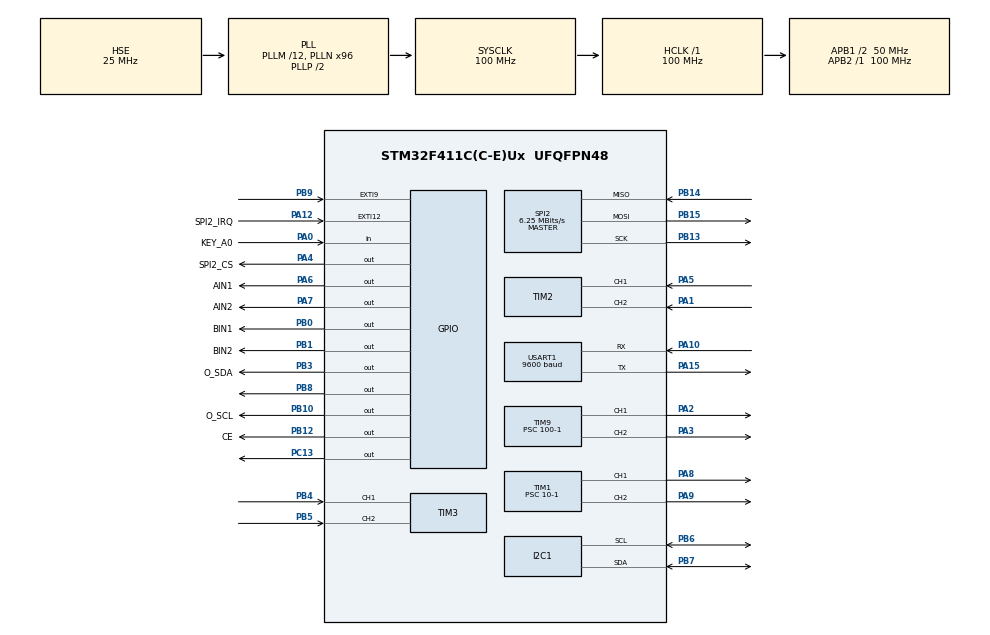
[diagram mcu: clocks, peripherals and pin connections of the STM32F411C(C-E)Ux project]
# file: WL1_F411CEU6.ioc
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Dma.Request0=USART1_RX
Dma.Request1=USART1_TX
Dma.Request2=SPI2_RX
Dma.Request3=SPI2_TX
Dma.SPI2_RX.2.Direction=DMA_PERIPH_TO_MEMORY
Dma.SPI2_RX.2.FIFOMode=DMA_FIFOMODE_DISABLE
Dma.SPI2_RX.2.Instance=DMA1_Stream3
Dma.SPI2_RX.2.MemDataAlignment=DMA_MDATAALIGN_BYTE
Dma.SPI2_RX.2.MemInc=DMA_MINC_ENABLE
Dma.SPI2_RX.2.Mode=DMA_NORMAL
Dma.SPI2_RX.2.PeriphDataAlignment=DMA_PDATAALIGN_BYTE
Dma.SPI2_RX.2.PeriphInc=DMA_PINC_DISABLE
Dma.SPI2_RX.2.Priority=DMA_PRIORITY_LOW
Dma.SPI2_TX.3.Direction=DMA_MEMORY_TO_PERIPH
Dma.SPI2_TX.3.FIFOMode=DMA_FIFOMODE_DISABLE
Dma.SPI2_TX.3.Instance=DMA1_Stream4
Dma.SPI2_TX.3.MemDataAlignment=DMA_MDATAALIGN_BYTE
Dma.SPI2_TX.3.MemInc=DMA_MINC_ENABLE
Dma.SPI2_TX.3.Mode=DMA_NORMAL
Dma.SPI2_TX.3.PeriphDataAlignment=DMA_PDATAALIGN_BYTE
Dma.SPI2_TX.3.PeriphInc=DMA_PINC_DISABLE
Dma.SPI2_TX.3.Priority=DMA_PRIORITY_LOW
Dma.USART1_RX.0.Direction=DMA_PERIPH_TO_MEMORY
Dma.USART1_RX.0.FIFOMode=DMA_FIFOMODE_DISABLE
Dma.USART1_RX.0.Instance=DMA2_Stream5
Dma.USART1_RX.0.MemDataAlignment=DMA_MDATAALIGN_BYTE
Dma.USART1_RX.0.MemInc=DMA_MINC_ENABLE
Dma.USART1_RX.0.Mode=DMA_NORMAL
Dma.USART1_RX.0.PeriphDataAlignment=DMA_PDATAALIGN_BYTE
Dma.USART1_RX.0.PeriphInc=DMA_PINC_DISABLE
Dma.USART1_RX.0.Priority=DMA_PRIORITY_LOW
Dma.USART1_TX.1.Direction=DMA_MEMORY_TO_PERIPH
Dma.USART1_TX.1.FIFOMode=DMA_FIFOMODE_DISABLE
Dma.USART1_TX.1.Instance=DMA2_Stream7
Dma.USART1_TX.1.MemDataAlignment=DMA_MDATAALIGN_BYTE
Dma.USART1_TX.1.MemInc=DMA_MINC_ENABLE
Dma.USART1_TX.1.Mode=DMA_NORMAL
Dma.USART1_TX.1.PeriphDataAlignment=DMA_PDATAALIGN_BYTE
Dma.USART1_TX.1.PeriphInc=DMA_PINC_DISABLE
Dma.USART1_TX.1.Priority=DMA_PRIORITY_LOW
FREERTOS.Tasks01=AppBootstrap,8,512,StartAppBootstrap,Default,NULL,Dynamic,NULL,NULL
FREERTOS.configENABLE_FPU=1
FREERTOS.configMINIMAL_STACK_SIZE=64
FREERTOS.configTOTAL_HEAP_SIZE=32768
FREERTOS.configUSE_IDLE_HOOK=1
FREERTOS.configUSE_NEWLIB_REENTRANT=1
FREERTOS.configUSE_STATS_FORMATTING_FUNCTIONS=1
I2C1.I2C_Mode=I2C_Fast
Mcu.Family=STM32F4
Mcu.Name=STM32F411C(C-E)Ux
Mcu.Package=UFQFPN48
NVIC.DMA1_Stream3_IRQn=true\:5\:0\:false\:false\:true\:true\:false\:true\:true
NVIC.DMA1_Stream4_IRQn=true\:5\:0\:false\:false\:true\:true\:false\:true\:true
NVIC.DMA2_Stream5_IRQn=true\:5\:0\:false\:false\:true\:false\:false\:true\:true
NVIC.DMA2_Stream7_IRQn=true\:5\:0\:false\:false\:true\:true\:false\:true\:true
NVIC.EXTI15_10_IRQn=true\:6\:0\:true\:false\:true\:true\:true\:true\:true
NVIC.PriorityGroup=NVIC_PRIORITYGROUP_4
NVIC.SPI2_IRQn=true\:5\:0\:true\:false\:true\:true\:true\:true\:true
NVIC.TIM2_IRQn=true\:6\:0\:true\:false\:true\:true\:true\:true\:true
NVIC.TIM3_IRQn=true\:6\:0\:true\:false\:true\:true\:true\:true\:true
NVIC.TIM5_IRQn=true\:15\:0\:false\:false\:true\:false\:false\:true\:true
NVIC.TimeBase=TIM5_IRQn
NVIC.TimeBaseIP=TIM5
NVIC.USART1_IRQn=true\:5\:0\:false\:false\:true\:true\:true\:true\:true
PA0.GPIO_Label=KEY_A0
PA0.GPIO_PuPd=GPIO_PULLUP
PA0.Signal=GPIO_Input
PA1.GPIO_PuPd=GPIO_PULLUP
PA1.Signal=S_TIM2_CH2
PA10.GPIO_PuPd=GPIO_PULLUP
PA10.Mode=Asynchronous
PA10.Signal=USART1_RX
PA12.GPIO_Label=SPI2_IRQ
PA12.GPIO_ModeDefaultEXTI=GPIO_MODE_IT_FALLING
PA12.GPIO_PuPd=GPIO_PULLUP
PA12.Signal=GPXTI12
PA13.Mode=Serial_Wire
PA13.Signal=SYS_JTMS-SWDIO
PA14.Mode=Serial_Wire
PA14.Signal=SYS_JTCK-SWCLK
PA15.GPIO_PuPd=GPIO_PULLUP
PA15.Mode=Asynchronous
PA15.Signal=USART1_TX
PA2.Signal=S_TIM9_CH1
PA3.Signal=S_TIM9_CH2
PA4.GPIO_Label=SPI2_CS
PA4.GPIO_Speed=GPIO_SPEED_FREQ_HIGH
PA4.Signal=GPIO_Output
PA5.GPIO_PuPd=GPIO_PULLUP
PA5.Signal=S_TIM2_CH1_ETR
PA6.GPIO_Label=AIN1
PA6.GPIO_Speed=GPIO_SPEED_FREQ_HIGH
PA6.Signal=GPIO_Output
PA7.GPIO_Label=AIN2
PA7.GPIO_Speed=GPIO_SPEED_FREQ_HIGH
PA7.Signal=GPIO_Output
PA8.Signal=S_TIM1_CH1
PA9.Signal=S_TIM1_CH2
PB0.GPIO_Label=BIN1
PB0.GPIO_Speed=GPIO_SPEED_FREQ_HIGH
PB0.Signal=GPIO_Output
PB1.GPIO_Label=BIN2
PB1.GPIO_Speed=GPIO_SPEED_FREQ_HIGH
PB1.Signal=GPIO_Output
PB10.GPIO_Label=O_SCL
PB10.GPIO_ModeDefaultOutputPP=GPIO_MODE_OUTPUT_OD
PB10.GPIO_PuPd=GPIO_NOPULL
PB10.GPIO_Speed=GPIO_SPEED_FREQ_HIGH
PB10.Signal=GPIO_Output
PB12.GPIO_Label=CE
PB12.GPIO_Speed=GPIO_SPEED_FREQ_HIGH
PB12.Signal=GPIO_Output
PB13.Mode=Full_Duplex_Master
PB13.Signal=SPI2_SCK
PB14.Mode=Full_Duplex_Master
PB14.Signal=SPI2_MISO
PB15.Mode=Full_Duplex_Master
PB15.Signal=SPI2_MOSI
PB3.GPIO_Label=O_SDA
PB3.GPIO_ModeDefaultOutputPP=GPIO_MODE_OUTPUT_OD
PB3.GPIO_PuPd=GPIO_NOPULL
PB3.GPIO_Speed=GPIO_SPEED_FREQ_HIGH
PB3.Signal=GPIO_Output
PB4.GPIO_PuPd=GPIO_PULLUP
PB4.Signal=S_TIM3_CH1
PB5.GPIO_PuPd=GPIO_PULLUP
PB5.Signal=S_TIM3_CH2
PB6.Mode=I2C
PB6.Signal=I2C1_SCL
PB7.Mode=I2C
PB7.Signal=I2C1_SDA
PB8.GPIO_ModeDefaultOutputPP=GPIO_MODE_OUTPUT_OD
PB8.GPIO_PuPd=GPIO_NOPULL
PB8.GPIO_Speed=GPIO_SPEED_FREQ_HIGH
PB8.Signal=GPIO_Output
PB9.Signal=GPXTI9
PC13-ANTI_TAMP.Signal=GPIO_Output
PC14-OSC32_IN.Mode=LSE-External-Oscillator
PC14-OSC32_IN.Signal=RCC_OSC32_IN
PC15-OSC32_OUT.Mode=LSE-External-Oscillator
PC15-OSC32_OUT.Signal=RCC_OSC32_OUT
PH0\ -\ OSC_IN.Mode=HSE-External-Oscillator
PH0\ -\ OSC_IN.Signal=RCC_OSC_IN
PH1\ -\ OSC_OUT.Mode=HSE-External-Oscillator
PH1\ -\ OSC_OUT.Signal=RCC_OSC_OUT
ProjectManager.HeapSize=0x200
ProjectManager.StackSize=0x400
ProjectManager.TargetToolchain=STM32CubeIDE
RCC.48MHZClocksFreq_Value=50000000
RCC.AHBFreq_Value=100000000
RCC.APB1CLKDivider=RCC_HCLK_DIV2
RCC.APB1Freq_Value=50000000
RCC.APB1TimFreq_Value=100000000
RCC.APB2Freq_Value=100000000
RCC.APB2TimFreq_Value=100000000
RCC.CortexFreq_Value=100000000
RCC.HCLKFreq_Value=100000000
RCC.HSE_VALUE=25000000
RCC.HSI_VALUE=16000000
RCC.PLLM=12
RCC.PLLN=96
RCC.PLLSourceVirtual=RCC_PLLSOURCE_HSE
RCC.RCC_RTC_Clock_Source=RCC_RTCCLKSOURCE_LSE
RCC.RCC_RTC_Clock_SourceVirtual=RCC_RTCCLKSOURCE_LSE
RCC.SYSCLKFreq_VALUE=100000000
RCC.SYSCLKSource=RCC_SYSCLKSOURCE_PLLCLK
RCC.VCOOutputFreq_Value=200000000
SH.S_TIM1_CH1.0=TIM1_CH1,PWM Generation1 CH1
SH.S_TIM1_CH2.0=TIM1_CH2,PWM Generation2 CH2
SH.S_TIM2_CH1_ETR.0=TIM2_CH1,Encoder_Interface
SH.S_TIM2_CH2.0=TIM2_CH2,Encoder_Interface
SH.S_TIM3_CH1.0=TIM3_CH1,Encoder_Interface
SH.S_TIM3_CH2.0=TIM3_CH2,Encoder_Interface
SH.S_TIM9_CH1.0=TIM9_CH1,PWM Generation1 CH1
SH.S_TIM9_CH2.0=TIM9_CH2,PWM Generation2 CH2
SPI2.BaudRatePrescaler=SPI_BAUDRATEPRESCALER_8
SPI2.CalculateBaudRate=6.25 MBits/s
SPI2.Direction=SPI_DIRECTION_2LINES
SPI2.Mode=SPI_MODE_MASTER
SPI2.VirtualType=VM_MASTER
TIM1.Channel-PWM\ Generation1\ CH1=TIM_CHANNEL_1
TIM1.Channel-PWM\ Generation2\ CH2=TIM_CHANNEL_2
TIM1.OCFastMode_PWM-PWM\ Generation1\ CH1=TIM_OCFAST_ENABLE
TIM1.OCFastMode_PWM-PWM\ Generation2\ CH2=TIM_OCFAST_ENABLE
TIM1.Period=1000-1
TIM1.Prescaler=10-1
TIM2.EncoderMode=TIM_ENCODERMODE_TI12
TIM2.IC1Filter=15
TIM2.IC2Filter=15
TIM3.EncoderMode=TIM_ENCODERMODE_TI12
TIM3.IC1Filter=15
TIM3.IC2Filter=15
TIM9.Channel-PWM\ Generation1\ CH1=TIM_CHANNEL_1
TIM9.Channel-PWM\ Generation2\ CH2=TIM_CHANNEL_2
TIM9.Period=10000-1
TIM9.Prescaler=100-1
USART1.BaudRate=9600
USART1.VirtualMode=VM_ASYNC
VP_FREERTOS_VS_CMSIS_V2.Mode=CMSIS_V2
VP_RTC_VS_RTC_Activate.Mode=RTC_Enabled
VP_SYS_VS_tim5.Mode=TIM5
VP_TIM1_VS_ClockSourceINT.Mode=Internal
VP_TIM9_VS_ClockSourceINT.Mode=Internal
board=custom

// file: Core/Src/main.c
/* USER CODE BEGIN Header */
/**
  ******************************************************************************
  * @file           : main.c
  * @brief          : Main program body
  ******************************************************************************
  * @attention
  *
  * Copyright (c) 2025 STMicroelectronics.
  * All rights reserved.
  *
  * This software is licensed under terms that can be found in the LICENSE file
  * in the root directory of this software component.
  * If no LICENSE file comes with this software, it is provided AS-IS.
  *
  ******************************************************************************
  */
/* USER CODE END Header */
#include "main.h"
#include "cmsis_os.h"
#include "dma.h"
#include "i2c.h"
#include "rtc.h"
#include "spi.h"
#include "tim.h"
#include "usart.h"
#include "gpio.h"

/* USER CODE BEGIN Includes */
#include "communication_config.h"

/* USER CODE END Includes */

void SystemClock_Config(void);
void MX_FREERTOS_Init(void);

int main(void)
{

  /* MCU Configuration--------------------------------------------------------*/

  /* Reset of all peripherals, Initializes the Flash interface and the Systick. */
  HAL_Init();

  /* Configure the system clock */
  SystemClock_Config();

  /* Initialize all configured peripherals */
  MX_GPIO_Init();
  MX_DMA_Init();
  MX_USART1_UART_Init();
  MX_I2C1_Init();
  MX_TIM2_Init();
  MX_TIM3_Init();
  MX_TIM9_Init();
  MX_RTC_Init();
#if WL1_ENABLE_NRF24
  MX_SPI2_Init();
#endif
  MX_TIM1_Init();
  /* USER CODE BEGIN 2 */
  /* ZX-D30 needs 300 ms after power-on before any UART data. Outputs are
     still inactive here; no AT handshake or BLE connection is required. */
  if (HAL_GetTick() < 300U) {
    HAL_Delay(300U - HAL_GetTick());
  }

  /* USER CODE END 2 */

  /* Init scheduler */
  osKernelInitialize();  /* Call init function for freertos objects (in cmsis_os2.c) */
  MX_FREERTOS_Init();

  /* Start scheduler */
  osKernelStart();

  /* We should never get here as control is now taken by the scheduler */

  /* Infinite loop */
  while (1)
  {

  }
}

void SystemClock_Config(void)
{
  RCC_OscInitTypeDef RCC_OscInitStruct = {0};
  RCC_ClkInitTypeDef RCC_ClkInitStruct = {0};

  /** Configure the main internal regulator output voltage
  */
  __HAL_RCC_PWR_CLK_ENABLE();
  __HAL_PWR_VOLTAGESCALING_CONFIG(PWR_REGULATOR_VOLTAGE_SCALE1);

  /** Initializes the RCC Oscillators according to the specified parameters
  * in the RCC_OscInitTypeDef structure.
  */
  RCC_OscInitStruct.OscillatorType = RCC_OSCILLATORTYPE_HSE|RCC_OSCILLATORTYPE_LSE;
  RCC_OscInitStruct.HSEState = RCC_HSE_ON;
  RCC_OscInitStruct.LSEState = RCC_LSE_ON;
  RCC_OscInitStruct.PLL.PLLState = RCC_PLL_ON;
  RCC_OscInitStruct.PLL.PLLSource = RCC_PLLSOURCE_HSE;
  RCC_OscInitStruct.PLL.PLLM = 12;
  RCC_OscInitStruct.PLL.PLLN = 96;
  RCC_OscInitStruct.PLL.PLLP = RCC_PLLP_DIV2;
  RCC_OscInitStruct.PLL.PLLQ = 4;
  if (HAL_RCC_OscConfig(&RCC_OscInitStruct) != HAL_OK)
  {
    Error_Handler();
  }

  /** Initializes the CPU, AHB and APB buses clocks
  */
  RCC_ClkInitStruct.ClockType = RCC_CLOCKTYPE_HCLK|RCC_CLOCKTYPE_SYSCLK
                              |RCC_CLOCKTYPE_PCLK1|RCC_CLOCKTYPE_PCLK2;
  RCC_ClkInitStruct.SYSCLKSource = RCC_SYSCLKSOURCE_PLLCLK;
  RCC_ClkInitStruct.AHBCLKDivider = RCC_SYSCLK_DIV1;
  RCC_ClkInitStruct.APB1CLKDivider = RCC_HCLK_DIV2;
  RCC_ClkInitStruct.APB2CLKDivider = RCC_HCLK_DIV1;

  if (HAL_RCC_ClockConfig(&RCC_ClkInitStruct, FLASH_LATENCY_3) != HAL_OK)
  {
    Error_Handler();
  }
}

void HAL_TIM_PeriodElapsedCallback(TIM_HandleTypeDef *htim)
{
  if (htim->Instance == TIM5)
  {
    HAL_IncTick();
  }
}

void Error_Handler(void)
{
  __disable_irq();
  while (1)
  {
  }
}

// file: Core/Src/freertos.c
/* USER CODE BEGIN Header */
/**
  ******************************************************************************
  * File Name          : freertos.c
  * Description        : Code for freertos applications
  ******************************************************************************
  * @attention
  *
  * Copyright (c) 2025 STMicroelectronics.
  * All rights reserved.
  *
  * This software is licensed under terms that can be found in the LICENSE file
  * in the root directory of this software component.
  * If no LICENSE file comes with this software, it is provided AS-IS.
  *
  ******************************************************************************
  */
/* USER CODE END Header */

#include "FreeRTOS.h"
#include "task.h"
#include "main.h"
#include "cmsis_os.h"

/* USER CODE BEGIN Includes */
#include "cpp_Interface.h"
#include "tim.h"
/* USER CODE END Includes */

/* USER CODE BEGIN Variables */
static signed char pcWriteBuffer[500];
/* USER CODE END Variables */
/* Definitions for AppBootstrap */
osThreadId_t AppBootstrapHandle;
const osThreadAttr_t AppBootstrap_attributes = {
  .name = "AppBootstrap",
  .stack_size = 512 * 4,
  .priority = (osPriority_t) osPriorityLow,
};

void StartAppBootstrap(void *argument);

void MX_FREERTOS_Init(void); /* (MISRA C 2004 rule 8.1) */

/* Hook prototypes */
void vApplicationIdleHook(void);

/* USER CODE BEGIN 2 */
void vApplicationIdleHook( void )
{
   /* vApplicationIdleHook() will only be called if configUSE_IDLE_HOOK is set
   to 1 in FreeRTOSConfig.h. It will be called on each iteration of the idle
   task. It is essential that code added to this hook function never attempts
   to block in any way (for example, call xQueueReceive() with a block time
   specified, or call vTaskDelay()). If the application makes use of the
   vTaskDelete() API function (as this demo application does) then it is also
   important that vApplicationIdleHook() is permitted to return to its calling
   function, because it is the responsibility of the idle task to clean up
   memory allocated by the kernel to any task that has since been deleted. */

//    int i;
//    vTaskList(pcWriteBuffer);
//    for (i = 0; i < 16; i++)
//        SendDataToUART1("-");
//    SendDataToUART1("\n\r");
//    SendDataToUART1("%s\n\r", pcWriteBuffer);
}
/* USER CODE END 2 */

void MX_FREERTOS_Init(void) {

  /* Create the thread(s) */
  /* creation of AppBootstrap */
  AppBootstrapHandle = osThreadNew(StartAppBootstrap, NULL, &AppBootstrap_attributes);

}

void StartAppBootstrap(void *argument)
{
  /* USER CODE BEGIN StartAppBootstrap */
  /* Run application composition after the scheduler is live, matching the
     app-main task model used by the reference project. CPP_Main creates the
     persistent application tasks; this bootstrap task then releases itself. */
  CPP_Main();
  vTaskDelete(NULL);
  for (;;) {}
  /* USER CODE END StartAppBootstrap */
}
